# nrf54lm20a_enga_application register map
Vendor: Nordic Semiconductor; Series: nrf54l; File version: 1
CPU: CM33 r0p4, little endian, MPU, FPU, 3 interrupt priority bits, 270 interrupts, 4 SAU regions
Registers are 32-bit, read-write, reset 0x0 unless marked. A register's access mark holds for its fields unless they carry their own. Offsets are from the block's base; [hi:lo] are bit positions; {n}, {i} and the like mark numbered series; 'fields as' and 'values as' point back to an identical list.

## GLOBAL_POWER_NS — Power control 0
Base 0x4010E000; alternate view of GLOBAL_CLOCK_NS
Same registers: GLOBAL_POWER_S 0x5010E000 (alternate view of GLOBAL_CLOCK_S)
0x30 TASKS_CONSTLAT wo — Enable Constant Latency mode
  [0] TASKS_CONSTLAT
    1=Trigger task
0x34 TASKS_LOWPWR wo — Enable Low-power mode (variable latency)
  [0] TASKS_LOWPWR
    1=Trigger task
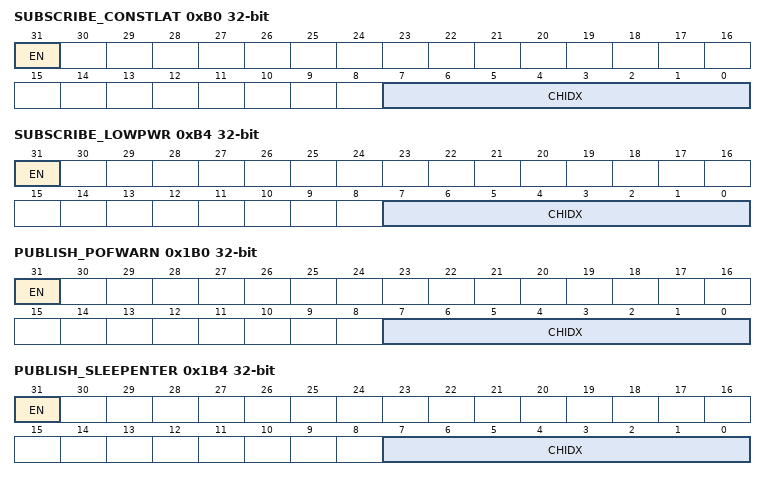
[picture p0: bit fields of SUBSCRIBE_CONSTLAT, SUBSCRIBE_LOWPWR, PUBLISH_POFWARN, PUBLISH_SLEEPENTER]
0xB0 SUBSCRIBE_CONSTLAT — Subscribe configuration for task CONSTLAT
  [31] EN
    0=Disabled (Disable subscription); 1=Enabled (Enable subscription)
  [7:0] CHIDX — DPPI channel that task CONSTLAT will subscribe to
0xB4 SUBSCRIBE_LOWPWR — Subscribe configuration for task LOWPWR
  [31] EN
    values as SUBSCRIBE_CONSTLAT.EN
  [7:0] CHIDX — DPPI channel that task LOWPWR will subscribe to
0x130 EVENTS_POFWARN — Power failure warning
  [0] EVENTS_POFWARN
    0=NotGenerated (Event not generated); 1=Generated (Event generated)
0x134 EVENTS_SLEEPENTER — CPU entered WFI/WFE sleep
  [0] EVENTS_SLEEPENTER
    values as EVENTS_POFWARN.EVENTS_POFWARN
0x138 EVENTS_SLEEPEXIT — CPU exited WFI/WFE sleep
  [0] EVENTS_SLEEPEXIT
    values as EVENTS_POFWARN.EVENTS_POFWARN
0x1B0 PUBLISH_POFWARN — Publish configuration for event POFWARN
  [31] EN
    0=Disabled (Disable publishing); 1=Enabled (Enable publishing)
  [7:0] CHIDX — DPPI channel that event POFWARN will publish to
0x1B4 PUBLISH_SLEEPENTER — Publish configuration for event SLEEPENTER
  [31] EN
    values as PUBLISH_POFWARN.EN
  [7:0] CHIDX — DPPI channel that event SLEEPENTER will publish to
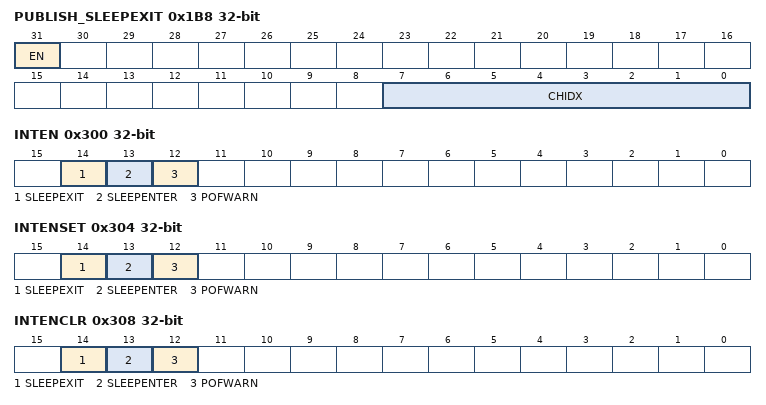
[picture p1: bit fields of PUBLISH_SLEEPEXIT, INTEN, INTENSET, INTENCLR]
0x1B8 PUBLISH_SLEEPEXIT — Publish configuration for event SLEEPEXIT
  [31] EN
    values as PUBLISH_POFWARN.EN
  [7:0] CHIDX — DPPI channel that event SLEEPEXIT will publish to
0x300 INTEN — Enable or disable interrupt
  [all] fields
    0=Disabled; 1=Enabled
  [14] SLEEPEXIT — Enable or disable interrupt for event SLEEPEXIT
  [13] SLEEPENTER — Enable or disable interrupt for event SLEEPENTER
  [12] POFWARN — Enable or disable interrupt for event POFWARN
0x304 INTENSET — Enable interrupt
  [all] fields
    on read: 0=Disabled (Read: Disabled); 1=Enabled (Read: Enabled) | on write: 1=Set (Enable)
  [14] SLEEPEXIT write-1-sets — Write '1' to enable interrupt for event SLEEPEXIT
  [13] SLEEPENTER write-1-sets — Write '1' to enable interrupt for event SLEEPENTER
  [12] POFWARN write-1-sets — Write '1' to enable interrupt for event POFWARN
0x308 INTENCLR — Disable interrupt
  [all] fields
    on read: 0=Disabled (Read: Disabled); 1=Enabled (Read: Enabled) | on write: 1=Clear (Disable)
  [14] SLEEPEXIT write-1-clears — Write '1' to disable interrupt for event SLEEPEXIT
  [13] SLEEPENTER write-1-clears — Write '1' to disable interrupt for event SLEEPENTER
  [12] POFWARN write-1-clears — Write '1' to disable interrupt for event POFWARN
{0x500+4i} GPREGRET[{i}] (i=0..1) — Description collection: General purpose retention register
  [7:0] GPREGRET — General purpose retention register
0x520 CONSTLATSTAT ro — Status of constant latency
  [0] STATUS
    0=Disable (Constant latency disabled); 1=Enable (Constant latency enabled)

## GLOBAL_RESET_NS — Reset control 0
Base 0x4010E000; alternate view of GLOBAL_CLOCK_NS
Same registers: GLOBAL_RESET_S 0x5010E000 (alternate view of GLOBAL_CLOCK_S)
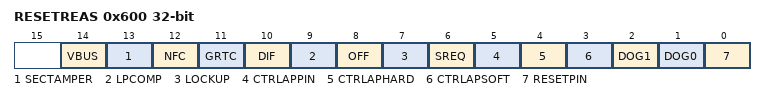
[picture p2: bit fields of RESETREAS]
0x600 RESETREAS — Reset reason
  [all] fields
    0=NotDetected; 1=Detected
  [14] VBUS — Reset after wakeup from System OFF mode due to VBUS rising into valid range
  [13] SECTAMPER — Reset due to illegal tampering of the device
  [12] NFC — Reset after wakeup from System OFF mode due to NFC field being detected
  [11] GRTC — Reset due to wakeup from GRTC
  [10] DIF — Reset triggered by Debug Interface
  [9] LPCOMP — Reset due to wakeup from System OFF mode when wakeup is triggered by ANADETECT signal from LPCOMP
  [8] OFF — Reset due to wakeup from System OFF mode when wakeup is triggered by DETECT signal from GPIO
  [7] LOCKUP — Reset from CPU lockup detected
  [6] SREQ — Reset from soft reset detected
  [5] CTRLAPPIN — Reset due to CTRL-AP pin reset
  [4] CTRLAPHARD — Reset due to CTRL-AP hard reset
  [3] CTRLAPSOFT — Soft reset from CTRL-AP detected
  [2] DOG1 — Reset from watchdog timer 1 detected
  [1] DOG0 — Reset from watchdog timer 0 detected
  [0] RESETPIN — Reset from pin reset detected
